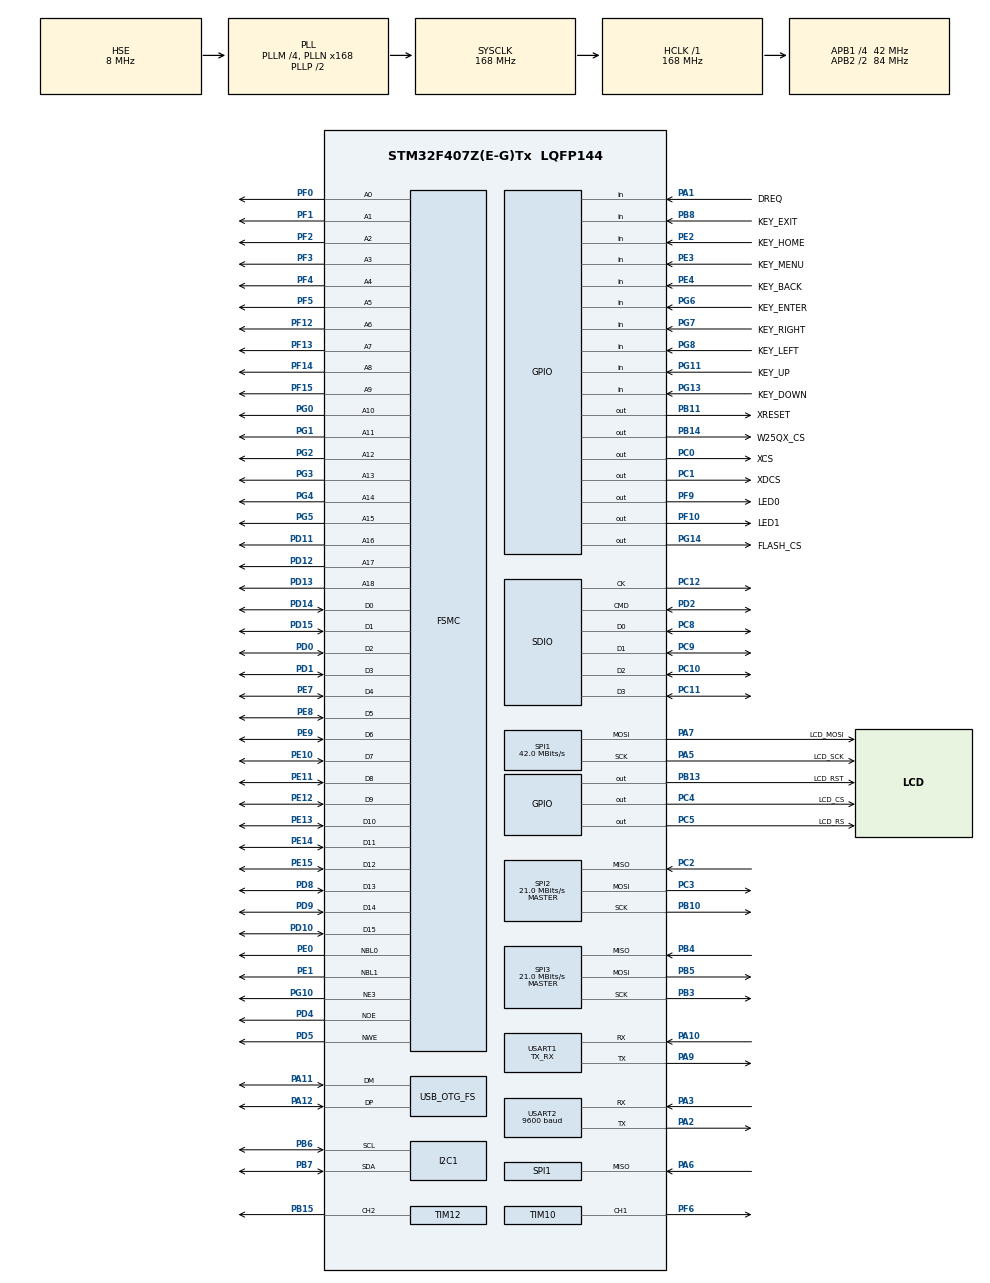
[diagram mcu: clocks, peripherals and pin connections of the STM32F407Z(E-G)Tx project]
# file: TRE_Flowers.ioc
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Dma.Request0=SDIO_TX
Dma.Request1=SDIO_RX
Dma.Request2=SPI1_TX
Dma.Request3=USART2_RX
Dma.SDIO_RX.1.Direction=DMA_PERIPH_TO_MEMORY
Dma.SDIO_RX.1.FIFOMode=DMA_FIFOMODE_ENABLE
Dma.SDIO_RX.1.FIFOThreshold=DMA_FIFO_THRESHOLD_FULL
Dma.SDIO_RX.1.Instance=DMA2_Stream6
Dma.SDIO_RX.1.MemBurst=DMA_MBURST_INC4
Dma.SDIO_RX.1.MemDataAlignment=DMA_MDATAALIGN_WORD
Dma.SDIO_RX.1.MemInc=DMA_MINC_ENABLE
Dma.SDIO_RX.1.Mode=DMA_PFCTRL
Dma.SDIO_RX.1.PeriphBurst=DMA_PBURST_INC4
Dma.SDIO_RX.1.PeriphDataAlignment=DMA_PDATAALIGN_WORD
Dma.SDIO_RX.1.PeriphInc=DMA_PINC_DISABLE
Dma.SDIO_RX.1.Priority=DMA_PRIORITY_HIGH
Dma.SDIO_TX.0.Direction=DMA_MEMORY_TO_PERIPH
Dma.SDIO_TX.0.FIFOMode=DMA_FIFOMODE_ENABLE
Dma.SDIO_TX.0.FIFOThreshold=DMA_FIFO_THRESHOLD_FULL
Dma.SDIO_TX.0.Instance=DMA2_Stream3
Dma.SDIO_TX.0.MemBurst=DMA_MBURST_INC4
Dma.SDIO_TX.0.MemDataAlignment=DMA_MDATAALIGN_WORD
Dma.SDIO_TX.0.MemInc=DMA_MINC_ENABLE
Dma.SDIO_TX.0.Mode=DMA_PFCTRL
Dma.SDIO_TX.0.PeriphBurst=DMA_PBURST_INC4
Dma.SDIO_TX.0.PeriphDataAlignment=DMA_PDATAALIGN_WORD
Dma.SDIO_TX.0.PeriphInc=DMA_PINC_DISABLE
Dma.SDIO_TX.0.Priority=DMA_PRIORITY_HIGH
Dma.SPI1_TX.2.Direction=DMA_MEMORY_TO_PERIPH
Dma.SPI1_TX.2.FIFOMode=DMA_FIFOMODE_DISABLE
Dma.SPI1_TX.2.Instance=DMA2_Stream5
Dma.SPI1_TX.2.MemDataAlignment=DMA_MDATAALIGN_BYTE
Dma.SPI1_TX.2.MemInc=DMA_MINC_ENABLE
Dma.SPI1_TX.2.Mode=DMA_NORMAL
Dma.SPI1_TX.2.PeriphDataAlignment=DMA_PDATAALIGN_BYTE
Dma.SPI1_TX.2.PeriphInc=DMA_PINC_DISABLE
Dma.SPI1_TX.2.Priority=DMA_PRIORITY_HIGH
Dma.USART2_RX.3.Direction=DMA_PERIPH_TO_MEMORY
Dma.USART2_RX.3.FIFOMode=DMA_FIFOMODE_DISABLE
Dma.USART2_RX.3.Instance=DMA1_Stream5
Dma.USART2_RX.3.MemDataAlignment=DMA_MDATAALIGN_BYTE
Dma.USART2_RX.3.MemInc=DMA_MINC_ENABLE
Dma.USART2_RX.3.Mode=DMA_NORMAL
Dma.USART2_RX.3.PeriphDataAlignment=DMA_PDATAALIGN_BYTE
Dma.USART2_RX.3.PeriphInc=DMA_PINC_DISABLE
Dma.USART2_RX.3.Priority=DMA_PRIORITY_LOW
FATFS.USE_DMA_CODE_SD=1
FATFS._CODE_PAGE=936
FATFS._LFN_UNICODE=0
FATFS._MAX_SS=512
FATFS._MIN_SS=512
FATFS._STRF_ENCODE=3
FATFS._USE_LABEL=1
FATFS._USE_LFN=2
FSMC.AddressSetupTime3=0
FSMC.BusTurnAroundDuration3=0
FSMC.DataSetupTime3=10
FSMC.WriteOperation3=FSMC_WRITE_OPERATION_ENABLE
I2C1.I2C_Mode=I2C_Fast
Mcu.Family=STM32F4
Mcu.Name=STM32F407Z(E-G)Tx
Mcu.Package=LQFP144
NVIC.DMA1_Stream5_IRQn=true\:0\:0\:true\:false\:true\:false\:true\:true
NVIC.DMA2_Stream3_IRQn=true\:4\:0\:true\:false\:true\:false\:true\:true
NVIC.DMA2_Stream5_IRQn=true\:1\:0\:true\:false\:true\:false\:true\:true
NVIC.DMA2_Stream6_IRQn=true\:4\:0\:true\:false\:true\:false\:true\:true
NVIC.PriorityGroup=NVIC_PRIORITYGROUP_4
NVIC.SDIO_IRQn=true\:4\:0\:true\:false\:true\:true\:true\:true
NVIC.SPI1_IRQn=true\:1\:0\:true\:false\:true\:true\:true\:true
NVIC.SPI2_IRQn=true\:1\:0\:true\:false\:true\:true\:true\:true
NVIC.SPI3_IRQn=true\:3\:0\:true\:false\:true\:true\:true\:true
NVIC.TIM1_UP_TIM10_IRQn=true\:0\:0\:true\:false\:true\:false\:true\:true
NVIC.TimeBase=TIM1_UP_TIM10_IRQn
NVIC.TimeBaseIP=TIM1
NVIC.USART1_IRQn=true\:0\:0\:false\:false\:true\:true\:true\:true
NVIC.USART2_IRQn=true\:0\:0\:true\:false\:true\:true\:true\:true
PA1.GPIO_Label=DREQ
PA1.Signal=GPIO_Input
PA10.Mode=Asynchronous
PA10.Signal=USART1_RX
PA11.Mode=Device_Only
PA11.Signal=USB_OTG_FS_DM
PA12.Mode=Device_Only
PA12.Signal=USB_OTG_FS_DP
PA13.Mode=Serial_Wire
PA13.Signal=SYS_JTMS-SWDIO
PA14.Mode=Serial_Wire
PA14.Signal=SYS_JTCK-SWCLK
PA2.Mode=Asynchronous
PA2.Signal=USART2_TX
PA3.Mode=Asynchronous
PA3.Signal=USART2_RX
PA5.GPIO_Label=LCD_SCK
PA5.Mode=Full_Duplex_Master
PA5.Signal=SPI1_SCK
PA6.Mode=Full_Duplex_Master
PA6.Signal=SPI1_MISO
PA7.GPIO_Label=LCD_MOSI
PA7.Mode=Full_Duplex_Master
PA7.Signal=SPI1_MOSI
PA9.Mode=Asynchronous
PA9.Signal=USART1_TX
PB10.GPIO_Speed=GPIO_SPEED_FREQ_VERY_HIGH
PB10.Mode=Full_Duplex_Master
PB10.Signal=SPI2_SCK
PB11.GPIO_Label=XRESET                                            
PB11.GPIO_Speed=GPIO_SPEED_FREQ_HIGH
PB11.PinState=GPIO_PIN_SET
PB11.Signal=GPIO_Output
PB13.GPIO_Label=LCD_RST
PB13.GPIO_PuPd=GPIO_PULLUP
PB13.GPIO_Speed=GPIO_SPEED_FREQ_HIGH
PB13.Signal=GPIO_Output
PB14.GPIO_Label=W25QX_CS
PB14.GPIO_PuPd=GPIO_PULLUP
PB14.GPIO_Speed=GPIO_SPEED_FREQ_HIGH
PB14.PinState=GPIO_PIN_SET
PB14.Signal=GPIO_Output
PB15.GPIO_Speed=GPIO_SPEED_FREQ_HIGH
PB15.Signal=S_TIM12_CH2
PB3.GPIO_Speed=GPIO_SPEED_FREQ_VERY_HIGH
PB3.Mode=Full_Duplex_Master
PB3.Signal=SPI3_SCK
PB4.GPIO_Speed=GPIO_SPEED_FREQ_VERY_HIGH
PB4.Mode=Full_Duplex_Master
PB4.Signal=SPI3_MISO
PB5.GPIO_Speed=GPIO_SPEED_FREQ_VERY_HIGH
PB5.Mode=Full_Duplex_Master
PB5.Signal=SPI3_MOSI
PB6.Mode=I2C
PB6.Signal=I2C1_SCL
PB7.Mode=I2C
PB7.Signal=I2C1_SDA
PB8.GPIO_Label=KEY_EXIT
PB8.GPIO_PuPd=GPIO_PULLUP
PB8.Signal=GPIO_Input
PC0.GPIO_Label=XCS
PC0.GPIO_Speed=GPIO_SPEED_FREQ_HIGH
PC0.PinState=GPIO_PIN_SET
PC0.Signal=GPIO_Output
PC1.GPIO_Label=XDCS
PC1.GPIO_Speed=GPIO_SPEED_FREQ_HIGH
PC1.PinState=GPIO_PIN_SET
PC1.Signal=GPIO_Output
PC10.Mode=SD_4_bits_Wide_bus
PC10.Signal=SDIO_D2
PC11.Mode=SD_4_bits_Wide_bus
PC11.Signal=SDIO_D3
PC12.Mode=SD_4_bits_Wide_bus
PC12.Signal=SDIO_CK
PC2.GPIO_Speed=GPIO_SPEED_FREQ_VERY_HIGH
PC2.Mode=Full_Duplex_Master
PC2.Signal=SPI2_MISO
PC3.GPIO_Speed=GPIO_SPEED_FREQ_VERY_HIGH
PC3.Mode=Full_Duplex_Master
PC3.Signal=SPI2_MOSI
PC4.GPIO_Label=LCD_CS
PC4.GPIO_Speed=GPIO_SPEED_FREQ_HIGH
PC4.Signal=GPIO_Output
PC5.GPIO_Label=LCD_RS
PC5.GPIO_PuPd=GPIO_PULLUP
PC5.GPIO_Speed=GPIO_SPEED_FREQ_HIGH
PC5.Signal=GPIO_Output
PC8.Mode=SD_4_bits_Wide_bus
PC8.Signal=SDIO_D0
PC9.Mode=SD_4_bits_Wide_bus
PC9.Signal=SDIO_D1
PD0.Signal=FSMC_D2_DA2
PD1.Signal=FSMC_D3_DA3
PD10.Signal=FSMC_D15_DA15
PD11.Signal=FSMC_A16_CLE
PD12.Signal=FSMC_A17_ALE
PD13.Signal=FSMC_A18
PD14.Signal=FSMC_D0_DA0
PD15.Signal=FSMC_D1_DA1
PD2.Mode=SD_4_bits_Wide_bus
PD2.Signal=SDIO_CMD
PD4.Signal=FSMC_NOE
PD5.Signal=FSMC_NWE
PD8.Signal=FSMC_D13_DA13
PD9.Signal=FSMC_D14_DA14
PE0.Signal=FSMC_NBL0
PE1.Signal=FSMC_NBL1
PE10.Signal=FSMC_D7_DA7
PE11.Signal=FSMC_D8_DA8
PE12.Signal=FSMC_D9_DA9
PE13.Signal=FSMC_D10_DA10
PE14.Signal=FSMC_D11_DA11
PE15.Signal=FSMC_D12_DA12
PE2.GPIO_Label=KEY_HOME
PE2.GPIO_PuPd=GPIO_PULLUP
PE2.Signal=GPIO_Input
PE3.GPIO_Label=KEY_MENU
PE3.GPIO_PuPd=GPIO_PULLUP
PE3.Signal=GPIO_Input
PE4.GPIO_Label=KEY_BACK
PE4.GPIO_PuPd=GPIO_PULLUP
PE4.Signal=GPIO_Input
PE7.Signal=FSMC_D4_DA4
PE8.Signal=FSMC_D5_DA5
PE9.Signal=FSMC_D6_DA6
PF0.Signal=FSMC_A0
PF1.Signal=FSMC_A1
PF10.GPIO_Label=LED1
PF10.PinState=GPIO_PIN_SET
PF10.Signal=GPIO_Output
PF12.Signal=FSMC_A6
PF13.Signal=FSMC_A7
PF14.Signal=FSMC_A8
PF15.Signal=FSMC_A9
PF2.Signal=FSMC_A2
PF3.Signal=FSMC_A3
PF4.Signal=FSMC_A4
PF5.Signal=FSMC_A5
PF6.Signal=S_TIM10_CH1
PF9.GPIO_Label=LED0
PF9.PinState=GPIO_PIN_SET
PF9.Signal=GPIO_Output
PG0.Signal=FSMC_A10
PG1.Signal=FSMC_A11
PG10.Mode=NorPsramChipSelect3_3
PG10.Signal=FSMC_NE3
PG11.GPIO_Label=KEY_UP
PG11.GPIO_PuPd=GPIO_PULLUP
PG11.Signal=GPIO_Input
PG13.GPIO_Label=KEY_DOWN
PG13.GPIO_PuPd=GPIO_PULLUP
PG13.Signal=GPIO_Input
PG14.GPIO_Label=FLASH_CS
PG14.GPIO_PuPd=GPIO_PULLUP
PG14.GPIO_Speed=GPIO_SPEED_FREQ_HIGH
PG14.PinState=GPIO_PIN_SET
PG14.Signal=GPIO_Output
PG2.Signal=FSMC_A12
PG3.Signal=FSMC_A13
PG4.Signal=FSMC_A14
PG5.Signal=FSMC_A15
PG6.GPIO_Label=KEY_ENTER
PG6.GPIO_PuPd=GPIO_PULLUP
PG6.Signal=GPIO_Input
PG7.GPIO_Label=KEY_RIGHT
PG7.GPIO_PuPd=GPIO_PULLUP
PG7.Signal=GPIO_Input
PG8.GPIO_Label=KEY_LEFT
PG8.GPIO_PuPd=GPIO_PULLUP
PG8.Signal=GPIO_Input
PH0-OSC_IN.Mode=HSE-External-Oscillator
PH0-OSC_IN.Signal=RCC_OSC_IN
PH1-OSC_OUT.Mode=HSE-External-Oscillator
PH1-OSC_OUT.Signal=RCC_OSC_OUT
ProjectManager.HeapSize=0x00000000
ProjectManager.StackSize=0x2400
ProjectManager.TargetToolchain=MDK-ARM V5.32
RCC.48MHZClocksFreq_Value=48000000
RCC.AHBFreq_Value=168000000
RCC.APB1CLKDivider=RCC_HCLK_DIV4
RCC.APB1Freq_Value=42000000
RCC.APB1TimFreq_Value=84000000
RCC.APB2CLKDivider=RCC_HCLK_DIV2
RCC.APB2Freq_Value=84000000
RCC.APB2TimFreq_Value=168000000
RCC.CortexFreq_Value=168000000
RCC.EnbaleCSS=true
RCC.HCLKFreq_Value=168000000
RCC.HSE_VALUE=8000000
RCC.HSI_VALUE=16000000
RCC.LSE_VALUE=32768
RCC.PLLM=4
RCC.PLLN=168
RCC.PLLQ=7
RCC.SYSCLKFreq_VALUE=168000000
RCC.SYSCLKSource=RCC_SYSCLKSOURCE_PLLCLK
RCC.VCOOutputFreq_Value=336000000
SDIO.ClockDiv=3
SH.FSMC_A0.0=FSMC_A0,19b-a3
SH.FSMC_A1.0=FSMC_A1,19b-a3
SH.FSMC_A10.0=FSMC_A10,19b-a3
SH.FSMC_A11.0=FSMC_A11,19b-a3
SH.FSMC_A12.0=FSMC_A12,19b-a3
SH.FSMC_A13.0=FSMC_A13,19b-a3
SH.FSMC_A14.0=FSMC_A14,19b-a3
SH.FSMC_A15.0=FSMC_A15,19b-a3
SH.FSMC_A16_CLE.0=FSMC_A16,19b-a3
SH.FSMC_A17_ALE.0=FSMC_A17,19b-a3
SH.FSMC_A18.0=FSMC_A18,19b-a3
SH.FSMC_A2.0=FSMC_A2,19b-a3
SH.FSMC_A3.0=FSMC_A3,19b-a3
SH.FSMC_A4.0=FSMC_A4,19b-a3
SH.FSMC_A5.0=FSMC_A5,19b-a3
SH.FSMC_A6.0=FSMC_A6,19b-a3
SH.FSMC_A7.0=FSMC_A7,19b-a3
SH.FSMC_A8.0=FSMC_A8,19b-a3
SH.FSMC_A9.0=FSMC_A9,19b-a3
SH.FSMC_D0_DA0.0=FSMC_D0,16b-d3
SH.FSMC_D10_DA10.0=FSMC_D10,16b-d3
SH.FSMC_D11_DA11.0=FSMC_D11,16b-d3
SH.FSMC_D12_DA12.0=FSMC_D12,16b-d3
SH.FSMC_D13_DA13.0=FSMC_D13,16b-d3
SH.FSMC_D14_DA14.0=FSMC_D14,16b-d3
SH.FSMC_D15_DA15.0=FSMC_D15,16b-d3
SH.FSMC_D1_DA1.0=FSMC_D1,16b-d3
SH.FSMC_D2_DA2.0=FSMC_D2,16b-d3
SH.FSMC_D3_DA3.0=FSMC_D3,16b-d3
SH.FSMC_D4_DA4.0=FSMC_D4,16b-d3
SH.FSMC_D5_DA5.0=FSMC_D5,16b-d3
SH.FSMC_D6_DA6.0=FSMC_D6,16b-d3
SH.FSMC_D7_DA7.0=FSMC_D7,16b-d3
SH.FSMC_D8_DA8.0=FSMC_D8,16b-d3
SH.FSMC_D9_DA9.0=FSMC_D9,16b-d3
SH.FSMC_NBL0.0=FSMC_NBL0,2ByteEnable3
SH.FSMC_NBL1.0=FSMC_NBL1,2ByteEnable3
SH.FSMC_NOE.0=FSMC_NOE,Sram3
SH.FSMC_NWE.0=FSMC_NWE,Sram3
SH.S_TIM10_CH1.0=TIM10_CH1,PWM Generation1 CH1
SH.S_TIM12_CH2.0=TIM12_CH2,PWM Generation2 CH2
SPI1.BaudRatePrescaler=SPI_BAUDRATEPRESCALER_2
SPI1.CalculateBaudRate=42.0 MBits/s
SPI1.Direction=SPI_DIRECTION_2LINES
SPI1.Mode=SPI_MODE_MASTER
SPI1.VirtualType=VM_MASTER
SPI2.BaudRatePrescaler=SPI_BAUDRATEPRESCALER_2
SPI2.CalculateBaudRate=21.0 MBits/s
SPI2.Direction=SPI_DIRECTION_2LINES
SPI2.Mode=SPI_MODE_MASTER
SPI2.VirtualType=VM_MASTER
SPI3.BaudRatePrescaler=SPI_BAUDRATEPRESCALER_2
SPI3.CLKPolarity=SPI_POLARITY_LOW
SPI3.CalculateBaudRate=21.0 MBits/s
SPI3.Direction=SPI_DIRECTION_2LINES
SPI3.Mode=SPI_MODE_MASTER
SPI3.VirtualType=VM_MASTER
TIM10.Channel=TIM_CHANNEL_1
TIM10.Period=370-1
TIM10.Prescaler=168-1
TIM10.Pulse=185
TIM12.Channel-PWM\ Generation2\ CH2=TIM_CHANNEL_2
TIM12.Period=10000-1
TIM12.Prescaler=84-1
TIM12.Pulse-PWM\ Generation2\ CH2=5000
TIM6.AutoReloadPreload=TIM_AUTORELOAD_PRELOAD_ENABLE
TIM6.Period=65535
TIM6.Prescaler=84-1
USART1.Mode=MODE_TX_RX
USART1.VirtualMode=VM_ASYNC
USART2.BaudRate=9600
USART2.Mode=MODE_TX_RX
USART2.VirtualMode=VM_ASYNC
USB_OTG_FS.VirtualMode=Device_Only
VP_FATFS_VS_SDIO.Mode=SDIO
VP_RNG_VS_RNG.Mode=RNG_Activate
VP_SYS_VS_tim1.Mode=TIM1
VP_TIM10_VS_ClockSourceINT.Mode=Enable_Timer
VP_TIM6_VS_ClockSourceINT.Mode=Enable_Timer
board=custom

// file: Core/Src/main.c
/* USER CODE BEGIN Header */
/**
  ******************************************************************************
  * @file           : main.c
  * @brief          : Main program body
  ******************************************************************************
  * @attention
  *
  * Copyright (c) 2022 STMicroelectronics.
  * All rights reserved.
  *
  * This software is licensed under terms that can be found in the LICENSE file
  * in the root directory of this software component.
  * If no LICENSE file comes with this software, it is provided AS-IS.
  *
  ******************************************************************************
  */
/* USER CODE END Header */
#include "main.h"
#include "dma.h"
#include "fatfs.h"
#include "i2c.h"
#include "rng.h"
#include "sdio.h"
#include "spi.h"
#include "tim.h"
#include "usart.h"
#include "usb_otg.h"
#include "gpio.h"
#include "fsmc.h"

/* USER CODE BEGIN Includes */
#include "FreeRTOS.h"
#include "task.h"
#include "os_task.h"
#include "sys.h"

#include "devices.h"

#include "gui_port.h"
#include "player.h"

#include "lcd_test.h"
/* USER CODE END Includes */

/* USER CODE BEGIN PD */
#define TASK_IDLE_PRIO				10
#define TASK_IDLE_STACK_SIZE	512
static TaskHandle_t TaskIdle_Handler;
void idle_task(void *pvParameters);

/* USER CODE END PD */

/* USER CODE BEGIN PV */
OTS_t ots_idle;

/* USER CODE END PV */

void SystemClock_Config(void);
/* USER CODE BEGIN PFP */
static void arduboy_update(const unsigned char *image);
static void arduboy_delay(int ms);
/* USER CODE END PFP */

int main(void)
{

  /* MCU Configuration--------------------------------------------------------*/

  /* Reset of all peripherals, Initializes the Flash interface and the Systick. */
  HAL_Init();

  /* Configure the system clock */
  SystemClock_Config();

  /* Initialize all configured peripherals */
  MX_GPIO_Init();
  MX_USART1_UART_Init();
  MX_DMA_Init();
  MX_USART2_UART_Init();
  MX_SPI1_Init();
  MX_SPI2_Init();
  MX_SPI3_Init();
  MX_I2C1_Init();
  MX_TIM6_Init();
  MX_FSMC_Init();
  MX_SDIO_SD_Init();
  MX_FATFS_Init();
  MX_TIM10_Init();
  MX_USB_OTG_FS_PCD_Init();
  MX_RNG_Init();
  MX_TIM12_Init();
  /* USER CODE BEGIN 2 */

	//Device Init
	device_init();

  /* USER CODE END 2 */

  /* Infinite loop */
  /* USER CODE BEGIN WHILE */
	//OS Task Init
	os_task_init();
	{
		ots_idle.taskCode = idle_task;
		ots_idle.taskName = "idle_task";
		ots_idle.taskStackSize = TASK_IDLE_STACK_SIZE;
		ots_idle.taskParameters = NULL;
		ots_idle.taskPriority = TASK_IDLE_PRIO;
		ots_idle.taskHandler = &TaskIdle_Handler;

		if(!MP3_Init()) Debug("VS10xx init failed\n");
		atgm336_init(&huart2, &hdma_usart2_rx);
		gui_port_init();
//		os_task_start(&ots_idle);
		atgm336_start();
	}

	vTaskStartScheduler();
//  while (1)
//  {
    /* USER CODE END WHILE */

    /* USER CODE BEGIN 3 */
//  }
  /* USER CODE END 3 */
}

void SystemClock_Config(void)
{
  RCC_OscInitTypeDef RCC_OscInitStruct = {0};
  RCC_ClkInitTypeDef RCC_ClkInitStruct = {0};

  /** Configure the main internal regulator output voltage
  */
  __HAL_RCC_PWR_CLK_ENABLE();
  __HAL_PWR_VOLTAGESCALING_CONFIG(PWR_REGULATOR_VOLTAGE_SCALE1);

  /** Initializes the RCC Oscillators according to the specified parameters
  * in the RCC_OscInitTypeDef structure.
  */
  RCC_OscInitStruct.OscillatorType = RCC_OSCILLATORTYPE_HSE;
  RCC_OscInitStruct.HSEState = RCC_HSE_ON;
  RCC_OscInitStruct.PLL.PLLState = RCC_PLL_ON;
  RCC_OscInitStruct.PLL.PLLSource = RCC_PLLSOURCE_HSE;
  RCC_OscInitStruct.PLL.PLLM = 4;
  RCC_OscInitStruct.PLL.PLLN = 168;
  RCC_OscInitStruct.PLL.PLLP = RCC_PLLP_DIV2;
  RCC_OscInitStruct.PLL.PLLQ = 7;
  if (HAL_RCC_OscConfig(&RCC_OscInitStruct) != HAL_OK)
  {
    Error_Handler();
  }

  /** Initializes the CPU, AHB and APB buses clocks
  */
  RCC_ClkInitStruct.ClockType = RCC_CLOCKTYPE_HCLK|RCC_CLOCKTYPE_SYSCLK
                              |RCC_CLOCKTYPE_PCLK1|RCC_CLOCKTYPE_PCLK2;
  RCC_ClkInitStruct.SYSCLKSource = RCC_SYSCLKSOURCE_PLLCLK;
  RCC_ClkInitStruct.AHBCLKDivider = RCC_SYSCLK_DIV1;
  RCC_ClkInitStruct.APB1CLKDivider = RCC_HCLK_DIV4;
  RCC_ClkInitStruct.APB2CLKDivider = RCC_HCLK_DIV2;

  if (HAL_RCC_ClockConfig(&RCC_ClkInitStruct, FLASH_LATENCY_5) != HAL_OK)
  {
    Error_Handler();
  }

  /** Enables the Clock Security System
  */
  HAL_RCC_EnableCSS();
}

/* USER CODE BEGIN 4 */
void idle_task(void *pvParameters)
{
	for(;;)
	{

		vTaskDelay(1000);
		break;
	}

	vTaskDelete(*ots_idle.taskHandler);
}

/* USER CODE END 4 */

void HAL_TIM_PeriodElapsedCallback(TIM_HandleTypeDef *htim)
{
  if (htim->Instance == TIM1) {
    HAL_IncTick();
  }
}

void Error_Handler(void)
{
  /* USER CODE BEGIN Error_Handler_Debug */
  /* User can add his own implementation to report the HAL error return state */
  __disable_irq();
  while (1)
  {
		printf("error handle\n");
  }
  /* USER CODE END Error_Handler_Debug */
}
